# STM32L0x3 register map
File version: 1.7
CPU: CM0+ r0p0, little endian, MPU, no FPU, 2 interrupt priority bits
Registers are 32-bit, read-write, reset 0x0 unless marked. A register's access mark holds for its fields unless they carry their own. Offsets are from the block's base; [hi:lo] are bit positions; 'fields as' and 'values as' point back to an identical list.

## RNG — Random number generator
Base 0x40025000
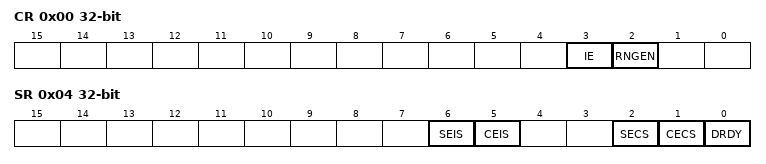
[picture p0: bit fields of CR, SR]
0x00 CR — control register
  [3] IE — Interrupt enable
    0=Disabled (RNG interrupt is disabled); 1=Enabled (RNG interrupt is enabled)
  [2] RNGEN — Random number generator enable
    0=Disabled (Random number generator is disabled); 1=Enabled (Random number generator is enabled)
0x04 SR access per field — status register
  [6] SEIS rw write-0-clears — Seed error interrupt status
    on write: 0=Clear flag | on read: 0=No faulty sequence detected; 1=Fault (At least one faulty sequence has been detected. See **SECS** bit description for details. An interrupt is pending if IE = 1 in the RNG_CR register.)
  [5] CEIS rw write-0-clears — Clock error interrupt status
    on write: 0=Clear flag | on read: 0=Correct (The RNG clock is correct); 1=Slow (The RNG has been detected too slow An interrupt is pending if IE = 1 in the RNG_CR register)
  [2] SECS ro — Seed error current status
    0=No faulty sequence has currently been detected. If the SEIS bit is set, this means that a faulty sequence was detected and the situation has been recovered.; 1=Fault (At least one faulty sequence has been detected - see ref manual for details)
  [1] CECS ro — Clock error current status
    0=Correct (The RNG clock is correct. If the CEIS bit is set, this means that a slow clock was detected and the situation has been recovered.); 1=Slow (The RNG clock is too slow)
  [0] DRDY ro — Data ready
    0=Invalid (The RNG_DR register is not yet valid, no random data is available); 1=Valid (The RNG_DR register contains valid random data. Once the RNG_DR register has been read, this bit returns to 0 until a new random value is generated.)
0x08 DR ro — data register
  [31:0] RNDATA — Random data

## IWDG — Independent watchdog
Base 0x40003000
0x00 KR 16-bit wo — Key register
  [15:0] KEY — Key value (write only, read 0x0000)
    0x5555=Unlock (Enable access to PR, RLR and WINR registers); 0xAAAA=Feed watchdog with RLR register value; 0xCCCC=Start the watchdog
0x04 PR 16-bit — Prescaler register
  [2:0] PR — Prescaler divider
    0=DivideBy4 (Divider /4); 1=DivideBy8 (Divider /8); 2=DivideBy16 (Divider /16); 3=DivideBy32 (Divider /32); 4=DivideBy64 (Divider /64); 5=DivideBy128 (Divider /128); other=DivideBy256 (Divider /256)
0x08 RLR 16-bit reset 0xFFF — Reload register
  [11:0] RL — Watchdog counter reload value
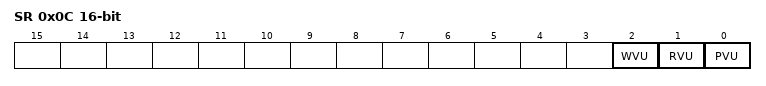
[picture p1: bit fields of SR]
0x0C SR 16-bit ro — Status register
  [2] WVU — Watchdog counter window value update
  [1] RVU — Watchdog counter reload value update
  [0] PVU — Watchdog prescaler value update
0x10 WINR 16-bit reset 0xFFF — Window register
  [11:0] WIN — Watchdog counter window value

## WWDG — System window watchdog
Base 0x40002C00
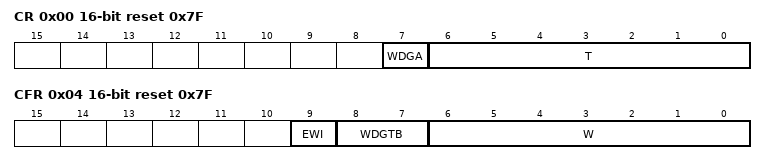
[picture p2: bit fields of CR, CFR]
0x00 CR 16-bit reset 0x7F — Control register
  [7] WDGA — Activation bit
    0=Disabled (Watchdog disabled); 1=Enabled (Watchdog enabled)
  [6:0] T — 7-bit counter (MSB to LSB)
0x04 CFR 16-bit reset 0x7F — Configuration register
  [9] EWI — Early wakeup interrupt
    on write: 1=Enable (interrupt occurs whenever the counter reaches the value 0x40)
  [8:7] WDGTB — Timer base
    0=Div1 (Counter clock (PCLK1 div 4096) div 1); 1=Div2 (Counter clock (PCLK1 div 4096) div 2); 2=Div4 (Counter clock (PCLK1 div 4096) div 4); 3=Div8 (Counter clock (PCLK1 div 4096) div 8)
  [6:0] W — 7-bit window value
0x08 SR 16-bit — Status register
  [0] EWIF write-0-clears — Early wakeup interrupt flag
    on read: 0=Finished (The EWI Interrupt Service Routine has been serviced); 1=Pending (The EWI Interrupt Service Routine has been triggered) | on write: 0=Finished (The EWI Interrupt Service Routine has been serviced)

## CRS — Clock recovery system
Base 0x40006C00
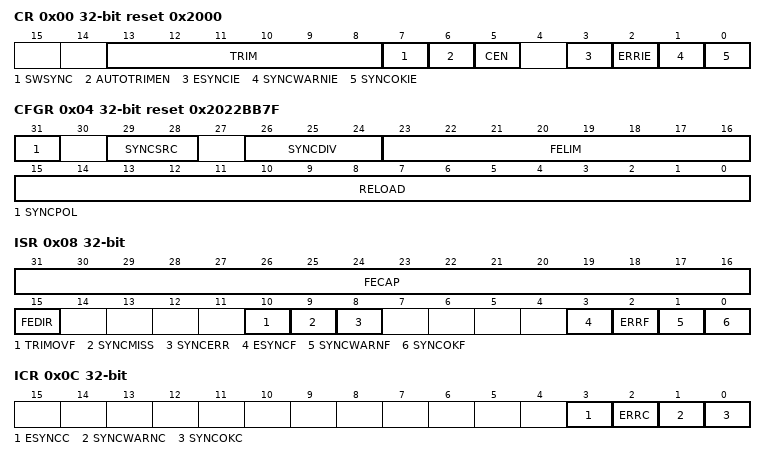
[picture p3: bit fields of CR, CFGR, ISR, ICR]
0x00 CR reset 0x2000 — control register
  [13:8] TRIM — HSI48 oscillator smooth trimming
  [7] SWSYNC — Generate software SYNC event
    1=Sync (A software sync is generated)
  [6] AUTOTRIMEN — Automatic trimming enable
    0=Disabled (Automatic trimming disabled); 1=Enabled (Automatic trimming enabled)
  [5] CEN — Frequency error counter enable
    0=Disabled (Frequency error counter disabled); 1=Enabled (Frequency error counter enabled)
  [3] ESYNCIE — Expected SYNC interrupt enable
    0=Disabled (Interrupt disabled); 1=Enabled (Interrupt enabled)
  [2] ERRIE — Synchronization or trimming error interrupt enable
    values as ESYNCIE
  [1] SYNCWARNIE — SYNC warning interrupt enable
    values as ESYNCIE
  [0] SYNCOKIE — SYNC event OK interrupt enable
    values as ESYNCIE
0x04 CFGR reset 0x2022BB7F — configuration register
  [31] SYNCPOL — SYNC polarity selection
    0=RisingEdge (SYNC active on rising edge); 1=FallingEdge (SYNC active on falling edge)
  [29:28] SYNCSRC — SYNC signal source selection
    0=GPIO_AF (GPIO AF (crs_sync_in_1) selected as SYNC signal source); 1=LSE (LSE (crs_sync_in_2) selected as SYNC signal source); 2=USB_SOF (USB SOF (crs_sync_in_3) selected as SYNC signal source)
  [26:24] SYNCDIV — SYNC divider
    0=Div1 (SYNC not divided); 1=Div2 (SYNC divided by 2); 2=Div4 (SYNC divided by 4); 3=Div8 (SYNC divided by 8); 4=Div16 (SYNC divided by 16); 5=Div32 (SYNC divided by 32); 6=Div64 (SYNC divided by 64); 7=Div128 (SYNC divided by 128)
  [23:16] FELIM — Frequency error limit
  [15:0] RELOAD — Counter reload value
0x08 ISR ro — interrupt and status register
  [31:16] FECAP — Frequency error capture
  [15] FEDIR — Frequency error direction
    0=UpCounting (Error in up-counting direction); 1=DownCounting (Error in down-counting direction)
  [10] TRIMOVF — Trimming overflow or underflow
    0=NotSignaled (Signal not set); 1=Signaled (Signal set)
  [9] SYNCMISS — SYNC missed
    0=NotSignaled (Signal not set); 1=Signaled (Signal set)
  [8] SYNCERR — SYNC error
    0=NotSignaled (Signal not set); 1=Signaled (Signal set)
  [3] ESYNCF — Expected SYNC flag
    0=NotSignaled (Signal not set); 1=Signaled (Signal set)
  [2] ERRF — Error flag
    0=NotSignaled (Signal not set); 1=Signaled (Signal set)
  [1] SYNCWARNF — SYNC warning flag
    0=NotSignaled (Signal not set); 1=Signaled (Signal set)
  [0] SYNCOKF — SYNC event OK flag
    0=NotSignaled (Signal not set); 1=Signaled (Signal set)
0x0C ICR — interrupt flag clear register
  [all] fields
    1=Clear flag
  [3] ESYNCC — Expected SYNC clear flag
  [2] ERRC — Error clear flag
  [1] SYNCWARNC — SYNC warning clear flag
  [0] SYNCOKC — SYNC event OK clear flag
